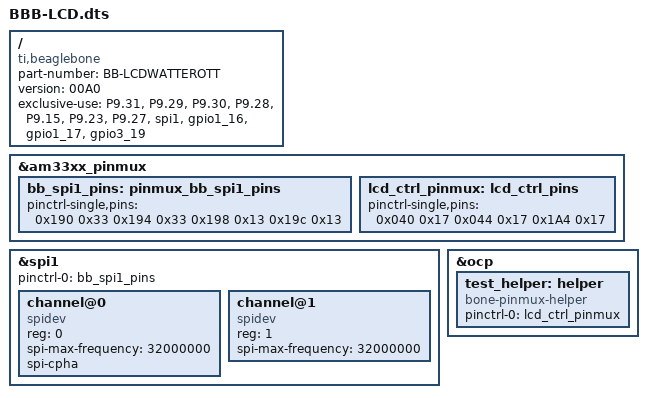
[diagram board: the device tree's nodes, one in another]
/*
 * This program is free software; you can redistribute it and/or modify
 * it under the terms of the GNU General Public License version 2 as
 * published by the Free Software Foundation.
 */
/dts-v1/;
/plugin/;

/ {
 compatible = "ti,beaglebone", "ti,beaglebone-black";

 /* identification */
 part-number = "BB-LCDWATTEROTT";
 version = "00A0";

 /* state the resources this cape uses */
 exclusive-use =
  /* the pin header uses */
  "P9.31", /* spi1_sclk */
  "P9.29", /* spi1_d0 */
  "P9.30", /* spi1_d1 */
  "P9.28", /* spi1_cs0 */
  "P9.15", /* gpio1_16 - reset */
  "P9.23", /* gpio1_17 - led */
  "P9.27", /* gpio3_19 - D/C */
  /* the hardware ip uses */
  "spi1",
  "gpio1_16",
  "gpio1_17",
  "gpio3_19";

 fragment@0 {
  target = <&am33xx_pinmux>;
  __overlay__ {
   /* default state has all gpios released and mode set to uart1 */
   bb_spi1_pins: pinmux_bb_spi1_pins {
    pinctrl-single,pins = <
     0x190 0x33 /* mcasp0_aclkx.spi1_sclk, INPUT_PULLUP | MODE3 */
     0x194 0x33 /* mcasp0_fsx.spi1_d0, INPUT_PULLUP | MODE3 */
     0x198 0x13 /* mcasp0_axr0.spi1_d1, OUTPUT_PULLUP | MODE3 */
     0x19c 0x13 /* mcasp0_ahclkr.spi1_cs0, OUTPUT_PULLUP | MODE3 */
    >;
   };
  };
 };

 fragment@1 {
  target = <&spi1>; /* spi1 is numbered correctly */
  __overlay__ {
   status = "okay";
   pinctrl-names = "default";
   pinctrl-0 = <&bb_spi1_pins>;

   #address-cells = <1>;
   #size-cells = <0>;

   channel@0 {
    #address-cells = <1>;
    #size-cells = <0>;

    compatible = "spidev";

    reg = <0>;
    spi-max-frequency = <32000000>;
    spi-cpha;
   };


   channel@1 {
    #address-cells = <1>;
    #size-cells = <0>;

    compatible = "spidev";

    reg = <1>;
    spi-max-frequency = <32000000>;
   };
  };
 };

 fragment@2 {
  target = <&am33xx_pinmux>;
  __overlay__ {
  status = "okay";
  lcd_ctrl_pinmux: lcd_ctrl_pins {
    pinctrl-single,pins = <
     0x040 0x17  /* gpio1_16  OUTPUT_PULLUP | MODE7 */
     0x044 0x17  /* gpio1_17  OUTPUT_PULLUP | MODE7 */
     0x1A4 0x17  /* gpio3_19  OUTPUT_PULLUP | MODE7 */
     >;
   };
  };
 };

 
 fragment@3 {
  target = <&ocp>;
  __overlay__ {
  test_helper: helper {
    compatible = "bone-pinmux-helper";
    pinctrl-names = "default";
    pinctrl-0 = <&lcd_ctrl_pinmux>;
    status = "okay";
   };
  };
 };
};
